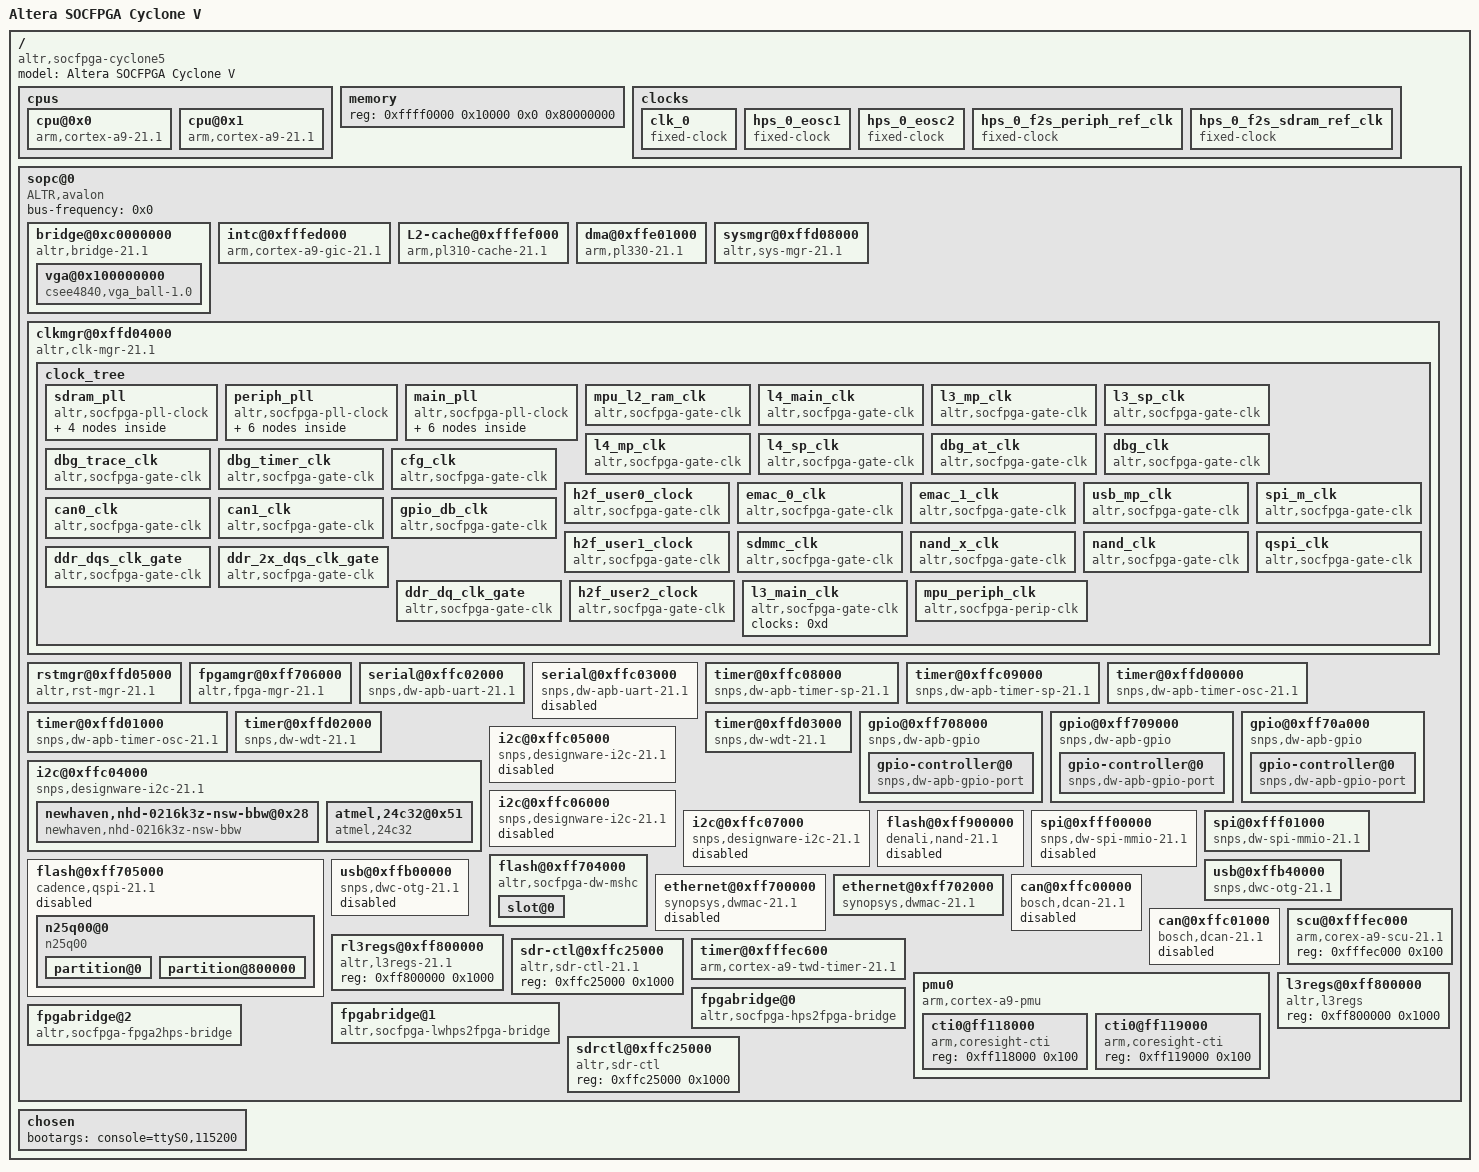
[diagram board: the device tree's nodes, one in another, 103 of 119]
/dts-v1/;

/ {
	model = "Altera SOCFPGA Cyclone V";
	compatible = "altr,socfpga-cyclone5", "altr,socfpga";
	#address-cells = <0x1>;
	#size-cells = <0x1>;

	cpus {
		#address-cells = <0x1>;
		#size-cells = <0x0>;

		cpu@0x0 {
			device_type = "cpu";
			compatible = "arm,cortex-a9-21.1", "arm,cortex-a9";
			reg = <0x0>;
			next-level-cache = <0x1>;
		};

		cpu@0x1 {
			device_type = "cpu";
			compatible = "arm,cortex-a9-21.1", "arm,cortex-a9";
			reg = <0x1>;
			next-level-cache = <0x1>;
		};
	};

	memory {
		device_type = "memory";
		reg = <0xffff0000 0x10000 0x0 0x80000000>;
	};

	clocks {
		#address-cells = <0x1>;
		#size-cells = <0x1>;

		clk_0 {
			compatible = "fixed-clock";
			#clock-cells = <0x0>;
			clock-frequency = <0x2faf080>;
			clock-output-names = "clk_0-clk";
			linux,phandle = <0x2>;
			phandle = <0x2>;
		};

		hps_0_eosc1 {
			compatible = "fixed-clock";
			#clock-cells = <0x0>;
			clock-frequency = <0x17d7840>;
			clock-output-names = "hps_0_eosc1-clk";
			linux,phandle = <0x5>;
			phandle = <0x5>;
		};

		hps_0_eosc2 {
			compatible = "fixed-clock";
			#clock-cells = <0x0>;
			clock-frequency = <0x17d7840>;
			clock-output-names = "hps_0_eosc2-clk";
			linux,phandle = <0x6>;
			phandle = <0x6>;
		};

		hps_0_f2s_periph_ref_clk {
			compatible = "fixed-clock";
			#clock-cells = <0x0>;
			clock-frequency = <0x0>;
			clock-output-names = "hps_0_f2s_periph_ref_clk-clk";
			linux,phandle = <0x7>;
			phandle = <0x7>;
		};

		hps_0_f2s_sdram_ref_clk {
			compatible = "fixed-clock";
			#clock-cells = <0x0>;
			clock-frequency = <0x0>;
			clock-output-names = "hps_0_f2s_sdram_ref_clk-clk";
			linux,phandle = <0x8>;
			phandle = <0x8>;
		};
	};

	sopc@0 {
		device_type = "soc";
		ranges;
		#address-cells = <0x1>;
		#size-cells = <0x1>;
		compatible = "ALTR,avalon", "simple-bus";
		bus-frequency = <0x0>;

		bridge@0xc0000000 {
			compatible = "altr,bridge-21.1", "simple-bus";
			reg = <0xc0000000 0x20000000 0xff200000 0x200000>;
			reg-names = "axi_h2f", "axi_h2f_lw";
			clocks = <0x2 0x2>;
			clock-names = "h2f_axi_clock", "h2f_lw_axi_clock";
			#address-cells = <0x2>;
			#size-cells = <0x1>;
			ranges = <0x1 0x0 0xff200000 0x8>;

			vga@0x100000000 {
				compatible = "csee4840,vga_ball-1.0";
				reg = <0x1 0x0 0x8>;
				clocks = <0x2>;
			};
		};

		intc@0xfffed000 {
			compatible = "arm,cortex-a9-gic-21.1", "arm,cortex-a9-gic";
			reg = <0xfffed000 0x1000 0xfffec100 0x100>;
			reg-names = "axi_slave0", "axi_slave1";
			interrupt-controller;
			#interrupt-cells = <0x3>;
			linux,phandle = <0x3>;
			phandle = <0x3>;
		};

		L2-cache@0xfffef000 {
			compatible = "arm,pl310-cache-21.1", "arm,pl310-cache";
			reg = <0xfffef000 0x1000>;
			interrupt-parent = <0x3>;
			interrupts = <0x0 0x26 0x4>;
			cache-level = <0x2>;
			cache-unified;
			arm,tag-latency = <0x1 0x1 0x1>;
			arm,data-latency = <0x2 0x1 0x1>;
			linux,phandle = <0x1>;
			phandle = <0x1>;
		};

		dma@0xffe01000 {
			compatible = "arm,pl330-21.1", "arm,pl330", "arm,primecell";
			reg = <0xffe01000 0x1000>;
			interrupt-parent = <0x3>;
			interrupts = <0x0 0x68 0x4>;
			clocks = <0x4>;
			#dma-cells = <0x1>;
			#dma-channels = <0x8>;
			#dma-requests = <0x20>;
			clock-names = "apb_pclk";
			copy-align = <0x3>;
			nr-irqs = <0x9>;
			nr-valid-peri = <0x9>;
		};

		sysmgr@0xffd08000 {
			compatible = "altr,sys-mgr-21.1", "altr,sys-mgr", "syscon", "syscon";
			reg = <0xffd08000 0x400>;
			cpu1-start-addr = <0xffd080c4>;
			linux,phandle = <0x25>;
			phandle = <0x25>;
		};

		clkmgr@0xffd04000 {
			compatible = "altr,clk-mgr-21.1", "altr,clk-mgr";
			reg = <0xffd04000 0x1000>;
			clocks = <0x5 0x6 0x7 0x8>;
			clock-names = "eosc1", "eosc2", "f2s_periph_ref_clk", "f2s_sdram_ref_clk";

			clock_tree {
				#size-cells = <0x0>;
				#address-cells = <0x1>;

				sdram_pll {
					compatible = "altr,socfpga-pll-clock";
					reg = <0xc0>;
					clocks = <0x5 0x6 0x8>;
					clock-names = "hps_0_eosc1", "hps_0_eosc2", "hps_0_f2s_sdram_ref_clk";
					#clock-cells = <0x0>;
					#address-cells = <0x1>;
					#size-cells = <0x0>;
					linux,phandle = <0x9>;
					phandle = <0x9>;

					ddr_dqs_clk {
						compatible = "altr,socfpga-perip-clk";
						reg = <0xc8>;
						clocks = <0x9>;
						#clock-cells = <0x0>;
						linux,phandle = <0x1a>;
						phandle = <0x1a>;
					};

					ddr_2x_dqs_clk {
						compatible = "altr,socfpga-perip-clk";
						reg = <0xcc>;
						clocks = <0x9>;
						#clock-cells = <0x0>;
						linux,phandle = <0x1b>;
						phandle = <0x1b>;
					};

					ddr_dq_clk {
						compatible = "altr,socfpga-perip-clk";
						reg = <0xd0>;
						clocks = <0x9>;
						#clock-cells = <0x0>;
						linux,phandle = <0x1c>;
						phandle = <0x1c>;
					};

					s2f_usr2_clk {
						compatible = "altr,socfpga-perip-clk";
						reg = <0xd4>;
						clocks = <0x9>;
						#clock-cells = <0x0>;
						linux,phandle = <0x1d>;
						phandle = <0x1d>;
					};
				};

				periph_pll {
					compatible = "altr,socfpga-pll-clock";
					reg = <0x80>;
					clocks = <0x5 0x6 0x7>;
					clock-names = "hps_0_eosc1", "hps_0_eosc2", "hps_0_f2s_periph_ref_clk";
					#clock-cells = <0x0>;
					#address-cells = <0x1>;
					#size-cells = <0x0>;
					linux,phandle = <0xa>;
					phandle = <0xa>;

					per_nand_mmc_clk {
						compatible = "altr,socfpga-perip-clk";
						reg = <0x94>;
						clocks = <0xa>;
						#clock-cells = <0x0>;
						linux,phandle = <0x17>;
						phandle = <0x17>;
					};

					per_base_clk {
						compatible = "altr,socfpga-perip-clk";
						reg = <0x98>;
						clocks = <0xa>;
						#clock-cells = <0x0>;
						linux,phandle = <0xf>;
						phandle = <0xf>;
					};

					per_qspi_clk {
						compatible = "altr,socfpga-perip-clk";
						reg = <0x90>;
						clocks = <0xa>;
						#clock-cells = <0x0>;
						linux,phandle = <0x19>;
						phandle = <0x19>;
					};

					s2f_usr1_clk {
						compatible = "altr,socfpga-perip-clk";
						reg = <0x9c>;
						clocks = <0xa>;
						#clock-cells = <0x0>;
						linux,phandle = <0x15>;
						phandle = <0x15>;
					};

					emac0_clk {
						compatible = "altr,socfpga-perip-clk";
						reg = <0x88>;
						clocks = <0xa>;
						#clock-cells = <0x0>;
						linux,phandle = <0x13>;
						phandle = <0x13>;
					};

					emac1_clk {
						compatible = "altr,socfpga-perip-clk";
						reg = <0x8c>;
						clocks = <0xa>;
						#clock-cells = <0x0>;
						linux,phandle = <0x14>;
						phandle = <0x14>;
					};
				};

				main_pll {
					compatible = "altr,socfpga-pll-clock";
					reg = <0x40>;
					clocks = <0x5>;
					#clock-cells = <0x0>;
					#address-cells = <0x1>;
					#size-cells = <0x0>;
					linux,phandle = <0xb>;
					phandle = <0xb>;

					cfg_s2f_usr0_clk {
						compatible = "altr,socfpga-perip-clk";
						reg = <0x5c>;
						clocks = <0xb>;
						#clock-cells = <0x0>;
						linux,phandle = <0x12>;
						phandle = <0x12>;
					};

					main_qspi_clk {
						compatible = "altr,socfpga-perip-clk";
						reg = <0x54>;
						clocks = <0xb>;
						#clock-cells = <0x0>;
						linux,phandle = <0x18>;
						phandle = <0x18>;
					};

					dbg_base_clk {
						compatible = "altr,socfpga-perip-clk";
						reg = <0x50>;
						clocks = <0xb 0x5>;
						clock-names = "main_pll", "hps_0_eosc1";
						#clock-cells = <0x0>;
						div-reg = <0xe8 0x0 0x9>;
						linux,phandle = <0x10>;
						phandle = <0x10>;
					};

					mpuclk {
						compatible = "altr,socfpga-perip-clk";
						reg = <0x48>;
						clocks = <0xb>;
						#clock-cells = <0x0>;
						div-reg = <0xe0 0x0 0x9>;
						linux,phandle = <0xc>;
						phandle = <0xc>;
					};

					mainclk {
						compatible = "altr,socfpga-perip-clk";
						reg = <0x4c>;
						clocks = <0xb>;
						#clock-cells = <0x0>;
						div-reg = <0xe4 0x0 0x9>;
						linux,phandle = <0xd>;
						phandle = <0xd>;
					};

					main_nand_sdmmc_clk {
						compatible = "altr,socfpga-perip-clk";
						reg = <0x58>;
						clocks = <0xb>;
						#clock-cells = <0x0>;
						linux,phandle = <0x16>;
						phandle = <0x16>;
					};
				};

				mpu_l2_ram_clk {
					compatible = "altr,socfpga-gate-clk";
					clocks = <0xc>;
					#clock-cells = <0x0>;
					fixed-divider = <0x2>;
				};

				l4_main_clk {
					compatible = "altr,socfpga-gate-clk";
					clocks = <0xd>;
					#clock-cells = <0x0>;
					clk-gate = <0x60 0x0>;
					linux,phandle = <0x4>;
					phandle = <0x4>;
				};

				l3_mp_clk {
					compatible = "altr,socfpga-gate-clk";
					clocks = <0xd>;
					#clock-cells = <0x0>;
					clk-gate = <0x60 0x1>;
					div-reg = <0x64 0x0 0x2>;
					linux,phandle = <0xe>;
					phandle = <0xe>;
				};

				l3_sp_clk {
					compatible = "altr,socfpga-gate-clk";
					clocks = <0xe>;
					#clock-cells = <0x0>;
					div-reg = <0x64 0x2 0x2>;
				};

				l4_mp_clk {
					compatible = "altr,socfpga-gate-clk";
					clocks = <0xd 0xf>;
					clock-names = "mainclk", "per_base_clk";
					#clock-cells = <0x0>;
					clk-gate = <0x60 0x2>;
					div-reg = <0x64 0x4 0x3>;
					linux,phandle = <0x1f>;
					phandle = <0x1f>;
				};

				l4_sp_clk {
					compatible = "altr,socfpga-gate-clk";
					clocks = <0xd 0xf>;
					clock-names = "mainclk", "per_base_clk";
					#clock-cells = <0x0>;
					clk-gate = <0x60 0x3>;
					div-reg = <0x64 0x7 0x3>;
					linux,phandle = <0x1e>;
					phandle = <0x1e>;
				};

				dbg_at_clk {
					compatible = "altr,socfpga-gate-clk";
					clocks = <0x10>;
					#clock-cells = <0x0>;
					clk-gate = <0x60 0x4>;
					div-reg = <0x68 0x0 0x2>;
					linux,phandle = <0x11>;
					phandle = <0x11>;
				};

				dbg_clk {
					compatible = "altr,socfpga-gate-clk";
					clocks = <0x11>;
					#clock-cells = <0x0>;
					clk-gate = <0x60 0x5>;
					div-reg = <0x68 0x2 0x2>;
				};

				dbg_trace_clk {
					compatible = "altr,socfpga-gate-clk";
					clocks = <0x10>;
					#clock-cells = <0x0>;
					clk-gate = <0x60 0x6>;
					div-reg = <0x6c 0x0 0x3>;
				};

				dbg_timer_clk {
					compatible = "altr,socfpga-gate-clk";
					clocks = <0x10>;
					#clock-cells = <0x0>;
					clk-gate = <0x60 0x7>;
				};

				cfg_clk {
					compatible = "altr,socfpga-gate-clk";
					clocks = <0x12>;
					#clock-cells = <0x0>;
					clk-gate = <0x60 0x8>;
				};

				h2f_user0_clock {
					compatible = "altr,socfpga-gate-clk";
					clocks = <0x12>;
					#clock-cells = <0x0>;
					clk-gate = <0x60 0x9>;
				};

				emac_0_clk {
					compatible = "altr,socfpga-gate-clk";
					clocks = <0x13>;
					#clock-cells = <0x0>;
					clk-gate = <0xa0 0x0>;
				};

				emac_1_clk {
					compatible = "altr,socfpga-gate-clk";
					clocks = <0x14>;
					#clock-cells = <0x0>;
					clk-gate = <0xa0 0x1>;
				};

				usb_mp_clk {
					compatible = "altr,socfpga-gate-clk";
					clocks = <0xf>;
					#clock-cells = <0x0>;
					clk-gate = <0xa0 0x2>;
					div-reg = <0xa4 0x0 0x3>;
					linux,phandle = <0x24>;
					phandle = <0x24>;
				};

				spi_m_clk {
					compatible = "altr,socfpga-gate-clk";
					clocks = <0xf>;
					#clock-cells = <0x0>;
					clk-gate = <0xa0 0x3>;
					div-reg = <0xa4 0x3 0x3>;
					linux,phandle = <0x21>;
					phandle = <0x21>;
				};

				can0_clk {
					compatible = "altr,socfpga-gate-clk";
					clocks = <0xf>;
					#clock-cells = <0x0>;
					clk-gate = <0xa0 0x4>;
					div-reg = <0xa4 0x6 0x3>;
					linux,phandle = <0x26>;
					phandle = <0x26>;
				};

				can1_clk {
					compatible = "altr,socfpga-gate-clk";
					clocks = <0xf>;
					#clock-cells = <0x0>;
					clk-gate = <0xa0 0x5>;
					div-reg = <0xa4 0x9 0x3>;
					linux,phandle = <0x27>;
					phandle = <0x27>;
				};

				gpio_db_clk {
					compatible = "altr,socfpga-gate-clk";
					clocks = <0xf>;
					#clock-cells = <0x0>;
					clk-gate = <0xa0 0x6>;
					div-reg = <0xa8 0x0 0x18>;
				};

				h2f_user1_clock {
					compatible = "altr,socfpga-gate-clk";
					clocks = <0x15>;
					#clock-cells = <0x0>;
					clk-gate = <0xa0 0x7>;
				};

				sdmmc_clk {
					compatible = "altr,socfpga-gate-clk";
					clocks = <0x7 0x16 0x17>;
					clock-names = "hps_0_f2s_periph_ref_clk", "main_nand_sdmmc_clk", "per_nand_mmc_clk";
					#clock-cells = <0x0>;
					clk-gate = <0xa0 0x8>;
					linux,phandle = <0x23>;
					phandle = <0x23>;
				};

				nand_x_clk {
					compatible = "altr,socfpga-gate-clk";
					clocks = <0x7 0x16 0x17>;
					clock-names = "hps_0_f2s_periph_ref_clk", "main_nand_sdmmc_clk", "per_nand_mmc_clk";
					#clock-cells = <0x0>;
					clk-gate = <0xa0 0x9>;
				};

				nand_clk {
					compatible = "altr,socfpga-gate-clk";
					clocks = <0x7 0x16 0x17>;
					clock-names = "hps_0_f2s_periph_ref_clk", "main_nand_sdmmc_clk", "per_nand_mmc_clk";
					#clock-cells = <0x0>;
					clk-gate = <0xa0 0xa>;
					fixed-divider = <0x4>;
					linux,phandle = <0x20>;
					phandle = <0x20>;
				};

				qspi_clk {
					compatible = "altr,socfpga-gate-clk";
					clocks = <0x7 0x18 0x19>;
					clock-names = "hps_0_f2s_periph_ref_clk", "main_qspi_clk", "per_qspi_clk";
					#clock-cells = <0x0>;
					clk-gate = <0xa0 0xb>;
					linux,phandle = <0x22>;
					phandle = <0x22>;
				};

				ddr_dqs_clk_gate {
					compatible = "altr,socfpga-gate-clk";
					clocks = <0x1a>;
					#clock-cells = <0x0>;
					clk-gate = <0xd8 0x0>;
				};

				ddr_2x_dqs_clk_gate {
					compatible = "altr,socfpga-gate-clk";
					clocks = <0x1b>;
					#clock-cells = <0x0>;
					clk-gate = <0xd8 0x1>;
				};

				ddr_dq_clk_gate {
					compatible = "altr,socfpga-gate-clk";
					clocks = <0x1c>;
					#clock-cells = <0x0>;
					clk-gate = <0xd8 0x2>;
				};

				h2f_user2_clock {
					compatible = "altr,socfpga-gate-clk";
					clocks = <0x1d>;
					#clock-cells = <0x0>;
					clk-gate = <0xd8 0x3>;
				};

				l3_main_clk {
					compatible = "altr,socfpga-gate-clk";
					clocks = <0xd>;
					#clock-cells = <0x0>;
				};

				mpu_periph_clk {
					compatible = "altr,socfpga-perip-clk";
					clocks = <0xc>;
					#clock-cells = <0x0>;
					reg = <0x0>;
					fixed-divider = <0x4>;
					linux,phandle = <0x28>;
					phandle = <0x28>;
				};
			};
		};

		rstmgr@0xffd05000 {
			compatible = "altr,rst-mgr-21.1", "altr,rst-mgr", "syscon", "syscon";
			reg = <0xffd05000 0x100>;
			#reset-cells = <0x1>;
			altr,modrst-offset = <0x10>;
		};

		fpgamgr@0xff706000 {
			compatible = "altr,fpga-mgr-21.1", "altr,fpga-mgr", "altr,socfpga-fpga-mgr";
			reg = <0xff706000 0x1000 0xffb90000 0x100>;
			reg-names = "axi_slave0", "axi_slave1";
			interrupt-parent = <0x3>;
			interrupts = <0x0 0xaf 0x4>;
			transport = "mmio";
		};

		serial@0xffc02000 {
			compatible = "snps,dw-apb-uart-21.1", "snps,dw-apb-uart";
			reg = <0xffc02000 0x100>;
			interrupt-parent = <0x3>;
			interrupts = <0x0 0xa2 0x4>;
			clocks = <0x1e>;
			reg-io-width = <0x4>;
			reg-shift = <0x2>;
			status = "okay";
			clock-frequency = <0x5f5e100>;
		};

		serial@0xffc03000 {
			compatible = "snps,dw-apb-uart-21.1", "snps,dw-apb-uart";
			reg = <0xffc03000 0x100>;
			interrupt-parent = <0x3>;
			interrupts = <0x0 0xa3 0x4>;
			clocks = <0x1e>;
			reg-io-width = <0x4>;
			reg-shift = <0x2>;
			status = "disabled";
			clock-frequency = <0x5f5e100>;
		};

		timer@0xffc08000 {
			compatible = "snps,dw-apb-timer-sp-21.1", "snps,dw-apb-timer-sp";
			reg = <0xffc08000 0x100>;
			interrupt-parent = <0x3>;
			interrupts = <0x0 0xa7 0x4>;
			clocks = <0x1e>;
			clock-names = "timer";
			clock-frequency = <0x5f5e100>;
		};

		timer@0xffc09000 {
			compatible = "snps,dw-apb-timer-sp-21.1", "snps,dw-apb-timer-sp";
			reg = <0xffc09000 0x100>;
			interrupt-parent = <0x3>;
			interrupts = <0x0 0xa8 0x4>;
			clocks = <0x1e>;
			clock-names = "timer";
			clock-frequency = <0x5f5e100>;
		};

		timer@0xffd00000 {
			compatible = "snps,dw-apb-timer-osc-21.1", "snps,dw-apb-timer-osc";
			reg = <0xffd00000 0x100>;
			interrupt-parent = <0x3>;
			interrupts = <0x0 0xa9 0x4>;
			clocks = <0x5>;
			clock-names = "timer";
			clock-frequency = <0x17d7840>;
		};

		timer@0xffd01000 {
			compatible = "snps,dw-apb-timer-osc-21.1", "snps,dw-apb-timer-osc";
			reg = <0xffd01000 0x100>;
			interrupt-parent = <0x3>;
			interrupts = <0x0 0xaa 0x4>;
			clocks = <0x5>;
			clock-names = "timer";
			clock-frequency = <0x17d7840>;
		};

		timer@0xffd02000 {
			compatible = "snps,dw-wdt-21.1", "snps,dw-wdt";
			reg = <0xffd02000 0x100>;
			interrupt-parent = <0x3>;
			interrupts = <0x0 0xab 0x4>;
			clocks = <0x5>;
			clock-names = "timer";
		};

		timer@0xffd03000 {
			compatible = "snps,dw-wdt-21.1", "snps,dw-wdt";
			reg = <0xffd03000 0x100>;
			interrupt-parent = <0x3>;
			interrupts = <0x0 0xac 0x4>;
			clocks = <0xf>;
			clock-names = "timer";
		};

		gpio@0xff708000 {
			compatible = "snps,dw-apb-gpio", "snps,dw-gpio-21.1", "snps,dw-gpio";
			reg = <0xff708000 0x100>;
			interrupt-parent = <0x3>;
			interrupts = <0x0 0xa4 0x4>;
			clocks = <0x1f>;
			#gpio-cells = <0x2>;
			gpio-controller;
			#address-cells = <0x1>;
			#size-cells = <0x0>;
			interrupt-controller;
			#interrupt-cells = <0x2>;

			gpio-controller@0 {
				compatible = "snps,dw-apb-gpio-port";
				gpio-controller;
				#gpio-cells = <0x2>;
				snps,nr-gpios = <0x1d>;
				reg = <0x0>;
				interrupt-controller;
				#interrupt-cells = <0x2>;
				interrupts = <0x0 0xa4 0x4>;
				interrupt-parent = <0x3>;
			};
		};

		gpio@0xff709000 {
			compatible = "snps,dw-apb-gpio", "snps,dw-gpio-21.1", "snps,dw-gpio";
			reg = <0xff709000 0x100>;
			interrupt-parent = <0x3>;
			interrupts = <0x0 0xa5 0x4>;
			clocks = <0x1f>;
			#gpio-cells = <0x2>;
			gpio-controller;
			#address-cells = <0x1>;
			#size-cells = <0x0>;
			interrupt-controller;
			#interrupt-cells = <0x2>;

			gpio-controller@0 {
				compatible = "snps,dw-apb-gpio-port";
				gpio-controller;
				#gpio-cells = <0x2>;
				snps,nr-gpios = <0x1d>;
				reg = <0x0>;
				interrupt-controller;
				#interrupt-cells = <0x2>;
				interrupts = <0x0 0xa5 0x4>;
				interrupt-parent = <0x3>;
			};
		};

		gpio@0xff70a000 {
			compatible = "snps,dw-apb-gpio", "snps,dw-gpio-21.1", "snps,dw-gpio";
			reg = <0xff70a000 0x100>;
			interrupt-parent = <0x3>;
			interrupts = <0x0 0xa6 0x4>;
			clocks = <0x1f>;
			#gpio-cells = <0x2>;
			gpio-controller;
			#address-cells = <0x1>;
			#size-cells = <0x0>;
			interrupt-controller;
			#interrupt-cells = <0x2>;

			gpio-controller@0 {
				compatible = "snps,dw-apb-gpio-port";
				gpio-controller;
				#gpio-cells = <0x2>;
				snps,nr-gpios = <0x1b>;
				reg = <0x0>;
				interrupt-controller;
				#interrupt-cells = <0x2>;
				interrupts = <0x0 0xa6 0x4>;
				interrupt-parent = <0x3>;
			};
		};

		i2c@0xffc04000 {
			compatible = "snps,designware-i2c-21.1", "snps,designware-i2c";
			reg = <0xffc04000 0x100>;
			interrupt-parent = <0x3>;
			interrupts = <0x0 0x9e 0x4>;
			clocks = <0x1e>;
			emptyfifo_hold_master = <0x1>;
			status = "okay";
			#address-cells = <0x1>;
			#size-cells = <0x0>;
			speed-mode = <0x0>;

			newhaven,nhd-0216k3z-nsw-bbw@0x28 {
				compatible = "newhaven,nhd-0216k3z-nsw-bbw";
				reg = <0x28>;
				height = <0x2>;
				width = <0x10>;
				brightness = <0x8>;
			};

			atmel,24c32@0x51 {
				compatible = "atmel,24c32";
				reg = <0x51>;
				pagesize = <0x20>;
			};
		};

		i2c@0xffc05000 {
			compatible = "snps,designware-i2c-21.1", "snps,designware-i2c";
			reg = <0xffc05000 0x100>;
			interrupt-parent = <0x3>;
			interrupts = <0x0 0x9f 0x4>;
			clocks = <0x1e>;
			emptyfifo_hold_master = <0x1>;
			status = "disabled";
		};

		i2c@0xffc06000 {
			compatible = "snps,designware-i2c-21.1", "snps,designware-i2c";
			reg = <0xffc06000 0x100>;
			interrupt-parent = <0x3>;
			interrupts = <0x0 0xa0 0x4>;
			clocks = <0x1e>;
			emptyfifo_hold_master = <0x1>;
			status = "disabled";
		};

		i2c@0xffc07000 {
			compatible = "snps,designware-i2c-21.1", "snps,designware-i2c";
			reg = <0xffc07000 0x100>;
			interrupt-parent = <0x3>;
			interrupts = <0x0 0xa1 0x4>;
			clocks = <0x1e>;
			emptyfifo_hold_master = <0x1>;
			status = "disabled";
		};

		flash@0xff900000 {
			compatible = "denali,nand-21.1", "denali,denali-nand-dt";
			reg = <0xff900000 0x10000 0xffb80000 0x10000>;
			reg-names = "nand_data", "denali_reg";
			interrupt-parent = <0x3>;
			interrupts = <0x0 0x90 0x4>;
			clocks = <0x20>;
			#address-cells = <0x1>;
			#size-cells = <0x1>;
			status = "disabled";
			bank-width = <0x2>;
			device-width = <0x1>;
		};

		spi@0xfff00000 {
			compatible = "snps,dw-spi-mmio-21.1", "snps,dw-spi-mmio", "snps,dw-apb-ssi";
			reg = <0xfff00000 0x100>;
			interrupt-parent = <0x3>;
			interrupts = <0x0 0x9a 0x4>;
			clocks = <0x21>;
			#address-cells = <0x1>;
			#size-cells = <0x0>;
			bus-num = <0x0>;
			num-chipselect = <0x4>;
			status = "disabled";
		};

		spi@0xfff01000 {
			compatible = "snps,dw-spi-mmio-21.1", "snps,dw-spi-mmio", "snps,dw-apb-ssi";
			reg = <0xfff01000 0x100>;
			interrupt-parent = <0x3>;
			interrupts = <0x0 0x9b 0x4>;
			clocks = <0x21>;
			#address-cells = <0x1>;
			#size-cells = <0x0>;
			bus-num = <0x0>;
			num-chipselect = <0x4>;
			status = "okay";
		};

		flash@0xff705000 {
			compatible = "cadence,qspi-21.1", "cadence,qspi", "cdns,qspi-nor";
			reg = <0xff705000 0x100 0xffa00000 0x100>;
			reg-names = "axi_slave0", "axi_slave1";
			interrupt-parent = <0x3>;
			interrupts = <0x0 0x97 0x4>;
			clocks = <0x22>;
			bus-num = <0x2>;
			fifo-depth = <0x80>;
			num-chipselect = <0x4>;
			status = "disabled";
			bank-width = <0x2>;
			device-width = <0x1>;
			master-ref-clk = <0x17d78400>;
			ext-decoder = <0x0>;
			#address-cells = <0x1>;
			#size-cells = <0x0>;

			n25q00@0 {
				#address-cells = <0x1>;
				#size-cells = <0x1>;
				compatible = "n25q00";
				reg = <0x0>;
				spi-max-frequency = <0x5f5e100>;
				page-size = <0x100>;
				block-size = <0x10>;
				m25p,fast-read;
				read-delay = <0x4>;
				tshsl-ns = <0x32>;
				tsd2d-ns = <0x32>;
				tchsh-ns = <0x4>;
				tslch-ns = <0x4>;

				partition@0 {
					label = "Flash 0 Raw Data";
					reg = <0x0 0x800000>;
				};

				partition@800000 {
					label = "Flash 1 jffs2 Filesystem";
					reg = <0x800000 0x800000>;
				};
			};
		};

		flash@0xff704000 {
			compatible = "altr,socfpga-dw-mshc";
			reg = <0xff704000 0x1000>;
			interrupt-parent = <0x3>;
			interrupts = <0x0 0x8b 0x4>;
			clocks = <0x1f 0x23>;
			clock-names = "biu", "ciu";
			fifo-depth = <0x400>;
			num-slots = <0x1>;
			status = "okay";
			bank-width = <0x2>;
			device-width = <0x1>;
			#address-cells = <0x1>;
			#size-cells = <0x0>;
			supports-highspeed;
			broken-cd;
			altr,dw-mshc-ciu-div = <0x3>;
			altr,dw-mshc-sdr-timing = <0x0 0x3>;

			slot@0 {
				reg = <0x0>;
				bus-width = <0x4>;
			};
		};

		usb@0xffb00000 {
			compatible = "snps,dwc-otg-21.1", "snps,dwc-otg", "snps,dwc2";
			reg = <0xffb00000 0x40000>;
			interrupt-parent = <0x3>;
			interrupts = <0x0 0x7d 0x4>;
			clocks = <0x24>;
			clock-names = "otg";
			dev-nperio-tx-fifo-size = <0x1000>;
			dev-perio-tx-fifo-size = "<512 512 512 512 512 512 512 512 512 512 512 512 512 512 512>";
			dev-rx-fifo-size = <0x200>;
			dev-tx-fifo-size = "<512 512 512 512 512 512 512 512 512 512 512 512 512 512 512>";
			dma-mask = <0xfffffff>;
			enable-dynamic-fifo = <0x1>;
			host-nperio-tx-fifo-size = <0xa00>;
			host-perio-tx-fifo-size = <0xa00>;
			host-rx-fifo-size = <0xa00>;
			phy-names = "usb2-phy";
			status = "disabled";
			ulpi-ddr = <0x0>;
			voltage-switch = <0x0>;
		};

		usb@0xffb40000 {
			compatible = "snps,dwc-otg-21.1", "snps,dwc-otg", "snps,dwc2";
			reg = <0xffb40000 0x40000>;
			interrupt-parent = <0x3>;
			interrupts = <0x0 0x80 0x4>;
			clocks = <0x24>;
			clock-names = "otg";
			dev-nperio-tx-fifo-size = <0x1000>;
			dev-perio-tx-fifo-size = "<512 512 512 512 512 512 512 512 512 512 512 512 512 512 512>";
			dev-rx-fifo-size = <0x200>;
			dev-tx-fifo-size = "<512 512 512 512 512 512 512 512 512 512 512 512 512 512 512>";
			dma-mask = <0xfffffff>;
			enable-dynamic-fifo = <0x1>;
			host-nperio-tx-fifo-size = <0xa00>;
			host-perio-tx-fifo-size = <0xa00>;
			host-rx-fifo-size = <0xa00>;
			phy-names = "usb2-phy";
			status = "okay";
			ulpi-ddr = <0x0>;
			voltage-switch = <0x0>;
		};

		ethernet@0xff700000 {
			compatible = "synopsys,dwmac-21.1", "altr,socfpga-stmmac", "snps,dwmac-3.70a", "snps,dwmac";
			reg = <0xff700000 0x2000>;
			interrupt-parent = <0x3>;
			interrupts = <0x0 0x73 0x4>;
			clocks = <0x13>;
			clock-names = "stmmaceth";
			interrupt-names = "macirq";
			rx-fifo-depth = <0x1000>;
			snps,multicast-filter-bins = <0x100>;
			snps,perfect-filter-entries = <0x80>;
			status = "disabled";
			tx-fifo-depth = <0x1000>;
			address-bits = <0x30>;
			max-frame-size = <0x5ee>;
			local-mac-address = [00 00 00 00 00 00];
		};

		ethernet@0xff702000 {
			compatible = "synopsys,dwmac-21.1", "altr,socfpga-stmmac", "snps,dwmac-3.70a", "snps,dwmac";
			reg = <0xff702000 0x2000>;
			interrupt-parent = <0x3>;
			interrupts = <0x0 0x78 0x4>;
			clocks = <0x14>;
			clock-names = "stmmaceth";
			interrupt-names = "macirq";
			rx-fifo-depth = <0x1000>;
			snps,multicast-filter-bins = <0x100>;
			snps,perfect-filter-entries = <0x80>;
			status = "okay";
			tx-fifo-depth = <0x1000>;
			address-bits = <0x30>;
			max-frame-size = <0x5ee>;
			local-mac-address = [00 00 00 00 00 00];
			phy-mode = "rgmii";
			phy-addr = <0xffffffff>;
			micrel-ksz9021rlrn-clk-skew = <0xa0e0>;
			micrel-ksz9021rlrn-rx-skew = <0x0>;
			altr,sysmgr-syscon = <0x25 0x60 0x2>;
			reset-names = "stmmaceth";
			resets = <0x21 0x21>;
			txd0-skew-ps = <0x0>;
			txd1-skew-ps = <0x0>;
			txd2-skew-ps = <0x0>;
			txd3-skew-ps = <0x0>;
			rxd0-skew-ps = <0x1a4>;
			rxd1-skew-ps = <0x1a4>;
			rxd2-skew-ps = <0x1a4>;
			rxd3-skew-ps = <0x1a4>;
			txen-skew-ps = <0x0>;
			txc-skew-ps = <0x744>;
			rxdv-skew-ps = <0x1a4>;
			rxc-skew-ps = <0x690>;
		};

		can@0xffc00000 {
			compatible = "bosch,dcan-21.1", "bosch,d_can";
			reg = <0xffc00000 0x1000>;
			interrupt-parent = <0x3>;
			interrupts = <0x0 0x83 0x4 0x0 0x84 0x4>;
			interrupt-names = "interrupt_sender0", "interrupt_sender1";
			clocks = <0x26>;
			status = "disabled";
		};

		can@0xffc01000 {
			compatible = "bosch,dcan-21.1", "bosch,d_can";
			reg = <0xffc01000 0x1000>;
			interrupt-parent = <0x3>;
			interrupts = <0x0 0x87 0x4 0x0 0x88 0x4>;
			interrupt-names = "interrupt_sender0", "interrupt_sender1";
			clocks = <0x27>;
			status = "disabled";
		};

		rl3regs@0xff800000 {
			compatible = "altr,l3regs-21.1", "altr,l3regs", "syscon";
			reg = <0xff800000 0x1000>;
		};

		sdr-ctl@0xffc25000 {
			compatible = "altr,sdr-ctl-21.1", "altr,sdr-ctl", "syscon";
			reg = <0xffc25000 0x1000>;
		};

		timer@0xfffec600 {
			compatible = "arm,cortex-a9-twd-timer-21.1", "arm,cortex-a9-twd-timer";
			reg = <0xfffec600 0x100>;
			interrupt-parent = <0x3>;
			interrupts = <0x1 0xd 0xf04>;
			clocks = <0x28>;
		};

		scu@0xfffec000 {
			compatible = "arm,corex-a9-scu-21.1", "arm,cortex-a9-scu";
			reg = <0xfffec000 0x100>;
		};

		pmu0 {
			#address-cells = <0x1>;
			#size-cells = <0x1>;
			compatible = "arm,cortex-a9-pmu";
			interrupt-parent = <0x3>;
			interrupts = <0x0 0xb0 0x4 0x0 0xb1 0x4>;
			ranges;

			cti0@ff118000 {
				compatible = "arm,coresight-cti";
				reg = <0xff118000 0x100>;
			};

			cti0@ff119000 {
				compatible = "arm,coresight-cti";
				reg = <0xff119000 0x100>;
			};
		};

		fpgabridge@0 {
			compatible = "altr,socfpga-hps2fpga-bridge";
			label = "hps2fpga";
			clocks = <0x4>;
		};

		fpgabridge@1 {
			compatible = "altr,socfpga-lwhps2fpga-bridge";
			label = "lwhps2fpga";
			clocks = <0x4>;
		};

		fpgabridge@2 {
			compatible = "altr,socfpga-fpga2hps-bridge";
			label = "fpga2hps";
			clocks = <0x4>;
		};

		l3regs@0xff800000 {
			compatible = "altr,l3regs", "syscon";
			reg = <0xff800000 0x1000>;
		};

		sdrctl@0xffc25000 {
			compatible = "altr,sdr-ctl", "syscon";
			reg = <0xffc25000 0x1000>;
		};
	};

	chosen {
		bootargs = "console=ttyS0,115200";
	};
};
